# STM32W108 register map
File version: 1.0
CPU: 
Registers are 32-bit, read-write, reset 0x0 unless marked. A register's access mark holds for its fields unless they carry their own. Offsets are from the block's base; [hi:lo] are bit positions; {n}, {i} and the like mark numbered series.

## EXTI — External interrupt/event controller
Base 0x4000A814
0x00 EXTI_PR — EXTI pending register
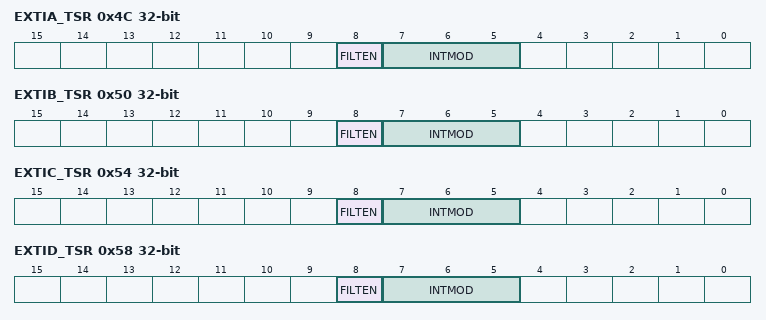
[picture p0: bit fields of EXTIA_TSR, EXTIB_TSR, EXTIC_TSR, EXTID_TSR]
0x4C EXTIA_TSR — EXTIA trigger source register
  [8] FILTEN, [7:5] INTMOD
0x50 EXTIB_TSR — EXTIB trigger source register
  [8] FILTEN, [7:5] INTMOD
0x54 EXTIC_TSR — EXTIC trigger source register
  [8] FILTEN, [7:5] INTMOD
0x58 EXTID_TSR — EXTID trigger source register
  [8] FILTEN, [7:5] INTMOD
0x1400 EXTIC_CR reset 0xF — EXTIC configuration register
  [4:0] GPIO_SEL
0x1404 EXTID_CR reset 0x10 — EXTID configuration register
  [4:0] GPIO_SEL

## GPIOA — General purpose I/Os
Base 0x4000B000
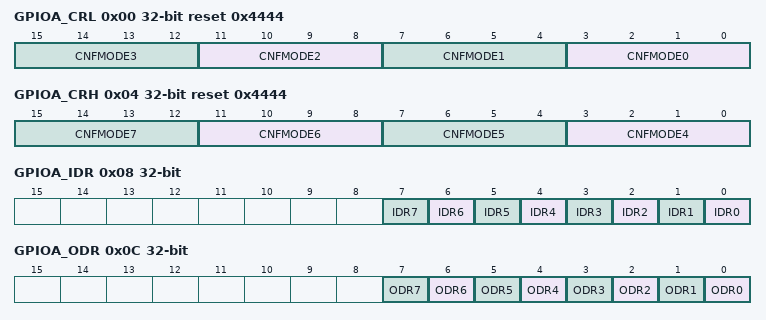
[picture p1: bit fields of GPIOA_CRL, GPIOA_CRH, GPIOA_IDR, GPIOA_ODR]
0x00 GPIOA_CRL reset 0x4444 — Port A configuration register (Low)
  [4n+3:4n] CNFMODE{n} (n=0..3)
0x04 GPIOA_CRH reset 0x4444 — Port A configuration register (High)
  [4n-13:4n-16] CNFMODE{n} (n=4..7)
0x08 GPIOA_IDR — Port A input data register
  [n] IDR{n} (n=0..7)
0x0C GPIOA_ODR — Port A output data register
  [n] ODR{n} (n=0..7)
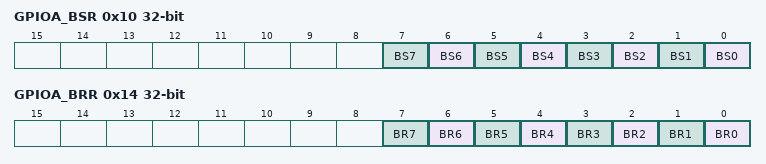
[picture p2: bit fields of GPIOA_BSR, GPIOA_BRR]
0x10 GPIOA_BSR — Port A bit set register
  [n] BS{n} (n=0..7)
0x14 GPIOA_BRR wo — Port A output clear register
  [n] BR{n} (n=0..7)

## GPIOB — General purpose I/Os
Base 0x4000B400
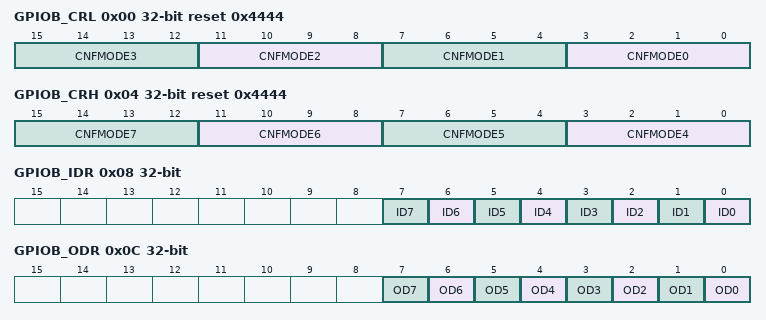
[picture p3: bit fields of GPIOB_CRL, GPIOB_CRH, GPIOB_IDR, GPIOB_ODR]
0x00 GPIOB_CRL reset 0x4444 — Port B configuration register (Low)
  [4n+3:4n] CNFMODE{n} (n=0..3)
0x04 GPIOB_CRH reset 0x4444 — Port B configuration register (High)
  [4n-13:4n-16] CNFMODE{n} (n=4..7)
0x08 GPIOB_IDR — Port B input data register
  [n] ID{n} (n=0..7)
0x0C GPIOB_ODR — Port B output data register
  [n] OD{n} (n=0..7)
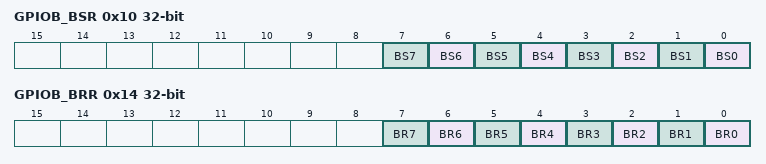
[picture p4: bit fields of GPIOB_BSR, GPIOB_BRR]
0x10 GPIOB_BSR — Port B bit set register
  [n] BS{n} (n=0..7)
0x14 GPIOB_BRR wo — Port B output clear register
  [n] BR{n} (n=0..7)

## GPIOC — General purpose I/Os
Base 0x4000B800
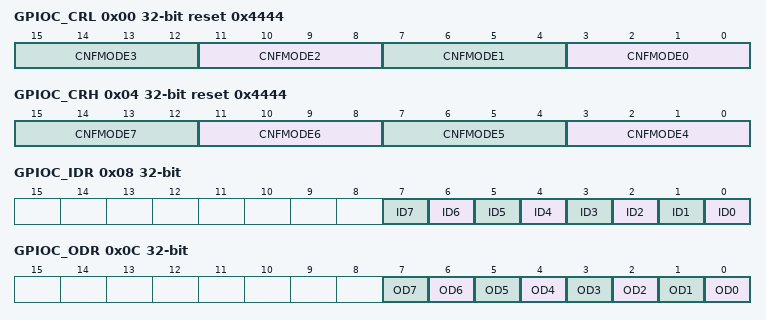
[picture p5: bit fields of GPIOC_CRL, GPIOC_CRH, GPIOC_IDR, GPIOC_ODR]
0x00 GPIOC_CRL reset 0x4444 — Port C configuration register (Low)
  [4n+3:4n] CNFMODE{n} (n=0..3)
0x04 GPIOC_CRH reset 0x4444 — Port C configuration register (High)
  [4n-13:4n-16] CNFMODE{n} (n=4..7)
0x08 GPIOC_IDR — Port C input data register
  [n] ID{n} (n=0..7)
0x0C GPIOC_ODR — Port C output data register
  [n] OD{n} (n=0..7)
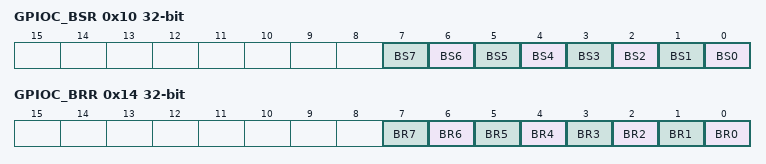
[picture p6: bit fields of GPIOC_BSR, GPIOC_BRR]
0x10 GPIOC_BSR — Port B bit set register
  [n] BS{n} (n=0..7)
0x14 GPIOC_BRR wo — Port C output clear register
  [n] BR{n} (n=0..7)

## GPIO_DBG — General purpose I/Os
Base 0x40004028
0x00 GPIO_PCTRACECR — Clock PC trace register
  [0] SEL — selects PC_TRACE source on bb_debug GPIO pins
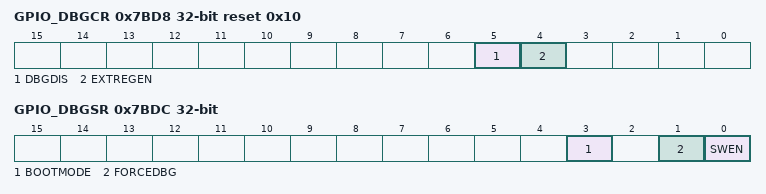
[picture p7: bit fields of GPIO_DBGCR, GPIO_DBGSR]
0x7BD8 GPIO_DBGCR reset 0x10 — GPIO debug configuration register
  [5] DBGDIS, [4] EXTREGEN
0x7BDC GPIO_DBGSR ro — GPIO debug status register
  [3] BOOTMODE, [1] FORCEDBG, [0] SWEN

## WDG — Watchdog timer
Base 0x40006000
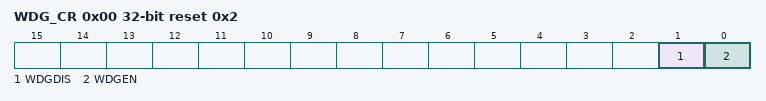
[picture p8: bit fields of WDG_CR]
0x00 WDG_CR reset 0x2 — WDG configuration register
  [1] WDGDIS, [0] WDGEN
0x04 WDG_KR wo — WDG key register
  [15:0] KEY
0x08 WDG_KICKSR wo — WDG kick-start register
  [15:0] KS

## CLK — Clock
Base 0x40000008
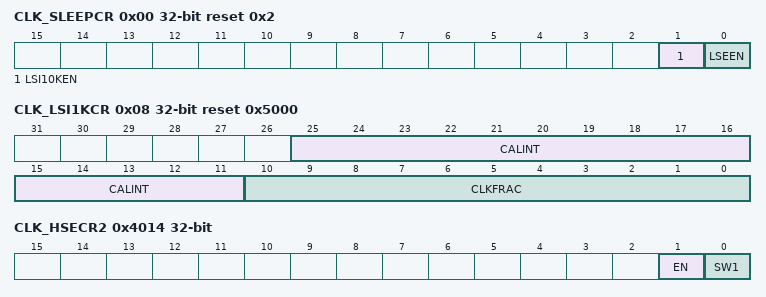
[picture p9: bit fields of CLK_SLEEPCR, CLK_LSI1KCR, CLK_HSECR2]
0x00 CLK_SLEEPCR reset 0x2 — Sleep timer control register
  [1] LSI10KEN — Enables 10kHz internal RC during deep
  [0] LSEEN — Enables 32kHz external XTAL
0x04 CLK_LSI10KCR — LSI Clock (10KHz) control register
  [3:0] TUNE — Tune value for clkrc
0x08 CLK_LSI1KCR reset 0x5000 — LSI Clock (1KHz) control register
  [25:11] CALINT — Divider value integer portion
  [10:0] CLKFRAC — Divider value fractional portion
0x3FFC CLK_HSECR1 reset 0xF — HSE Clock (24MHz) control register 1
  [3:0] BIASTRIM — Bias trim setting for 24MHz oscillator
0x4000 CLK_HSICR reset 0x17 — HSI Clock (12MHz) trim register
  [4:0] TUNE — Frequency trim setting for HF RC oscillator
0x4008 CLK_PERIODCR reset 0x200 — Clock period control register
  [1:0] MODE — Sets clock to be measured by CLK_PERIOD
0x400C CLK_PERIODSR ro — Clock period status register
  [15:0] PERIOD — Clock period measurement
0x4010 CLK_DITHERCR — Clock dither control register
  [0] DIS — Dither disable
0x4014 CLK_HSECR2 — HSE Clock (24MHz) control register 2
  [1] EN — MHz crystal oscillator is main clock
  [0] SW1 — OSCHF/XTAL is selected
0x4018 CLK_CPUCR — Clock source select register
  [0] SW2 — 12MHz/24MHz is selected
